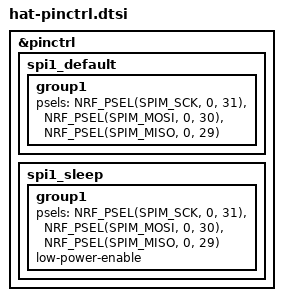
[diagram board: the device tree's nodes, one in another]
/*
 * Copyright (c) 2022 Nordic Semiconductor ASA
 * SPDX-License-Identifier: Apache-2.0
 */

&pinctrl {

	spi1_default: spi1_default {
		group1 {
			psels = <NRF_PSEL(SPIM_SCK, 0, 31)>,
				<NRF_PSEL(SPIM_MOSI, 0, 30)>,
				<NRF_PSEL(SPIM_MISO, 0, 29)>;
		};
	};

	spi1_sleep: spi1_sleep {
		group1 {
			psels = <NRF_PSEL(SPIM_SCK, 0, 31)>,
				<NRF_PSEL(SPIM_MOSI, 0, 30)>,
				<NRF_PSEL(SPIM_MISO, 0, 29)>;
			low-power-enable;
		};
	};

};
